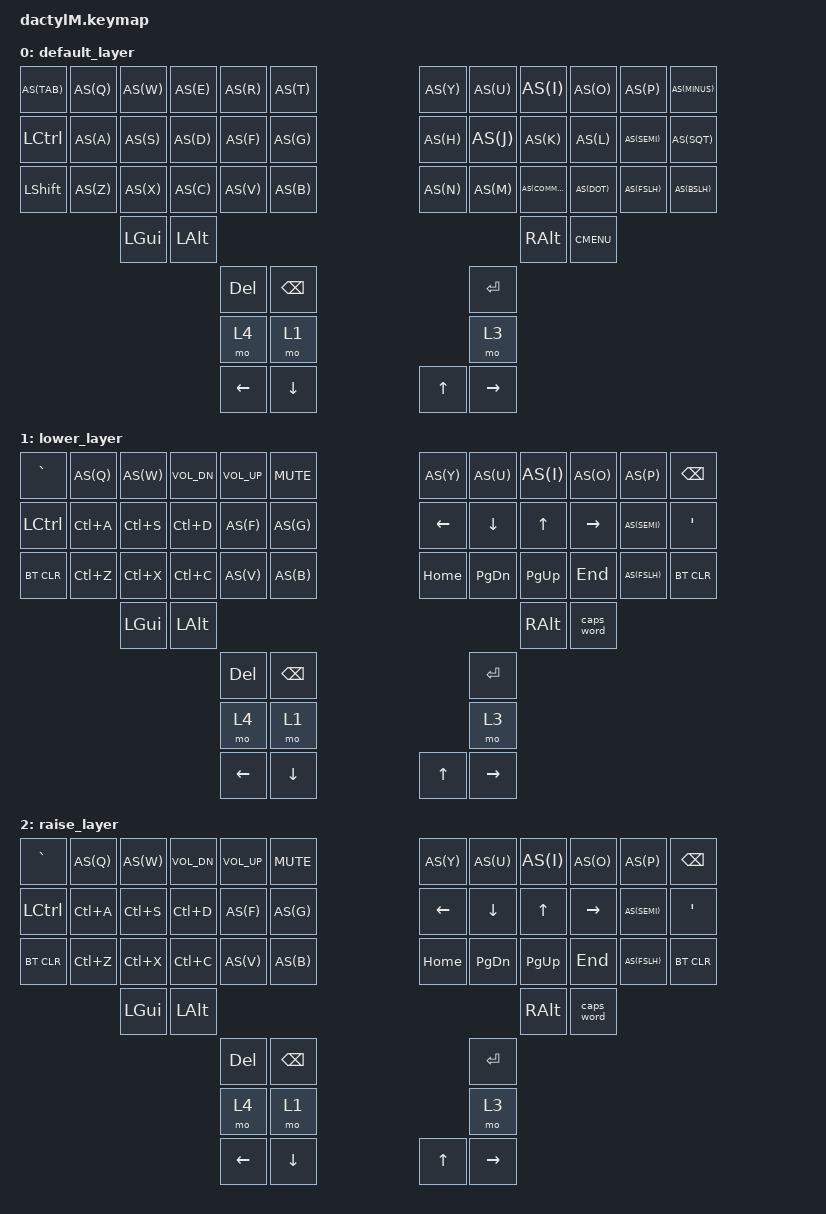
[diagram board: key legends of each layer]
/*
 * Copyright (c) 2020 The ZMK Contributors
 *
 * SPDX-License-Identifier: MIT
 */
/**/

#include <behaviors.dtsi>
#include <dt-bindings/zmk/keys.h>
#include <dt-bindings/zmk/bt.h>



#define DEFAULT 0
#define Movement 1
#define NumPad 2
#define Macro 3
#define Mouse 4

#define AS(keycode) &as LS(keycode) keycode

/ {
        behaviors {
            as: auto_shift {
                compatible = "zmk,behavior-hold-tap";
                label = "AUTO_SHIFT";
                #binding-cells = <2>;
                tapping_term_ms = <200>;
                quick_tap_ms = <10>;
                flavor = "tap-preferred";
                bindings = <&kp>, <&kp>;
            };
        };
        
        
    keymap {
        compatible = "zmk,keymap";

        default_layer {
// ------------------------------------------------------------------------------------------------------------
// |  TAB  |  Q  |  W  |  E   |  R   |  T    |                   |  Y   |  U     |  I    |  O   |   P   | BKSPC  |
// |  CTRL |  A  |  S  |  D   |  F   |  G    |                   |  H   |  J     |  K    |  L   |   ;   |   '    |
// | SHIFT |  Z  |  X  |  C   |  V   |  B    |                   |  N   |  M     |  ,    |  .   |   /   | SHIFT  |
//               | GUI | ALT  |                                                  | ALT   | GUI  |
//                            | DEL  | BKSPC |                   		|  ENTR  |
//                            | Lyr4 | Lyr1  |                   		| Lyr3  |
//                            | LEFT | DOWN  |                   | UP    | RIGHT |
            bindings = <
AS(TAB)   AS(Q)  AS(W)    AS(E)    AS(R)     AS(T)                       AS(Y)  AS(U)     AS(I)     AS(O)    AS(P)    AS(MINUS)
&kp LCTRL AS(A)  AS(S)    AS(D)    AS(F)     AS(G)                       AS(H)  AS(J)     AS(K)     AS(L)    AS(SEMI) AS(SQT)
&kp LSHFT AS(Z)  AS(X)    AS(C)    AS(V)     AS(B)                       AS(N)  AS(M)     AS(COMMA) AS(DOT)  AS(FSLH) AS(BSLH)
                 &kp LGUI &kp LALT                                                        &kp RALT  &kp K_CMENU
                                    &kp DELETE&kp BSPC                    		  &kp ENTER
                                    &mo 4     &mo 1                       		  &mo 3 
                                    &kp LEFT   &kp DOWN                   &kp UP  &kp RIGHT  
            >;
        };

        lower_layer {
// TODO: Some binds are waiting for shifted keycode support.
// ------------------------------------------------------------------------------------------------------------
// | `     |   1 |   2 |   3  |   4  |   5  |                   |   6  |   7   |   8   |   9  |    0  |  F12  |
// |       |  !  |  @  |  #   |  $   |  %   |                   |  ^   |  &    |  *    |  (   |   )   |   |   |
// |       |  =  |  -  |  +   |  {   |  }   |        |  |       |  [   |  ]    |  ;    |  :   |   \   |       |
//               |     |      |      |      |        |  |       |      |       |       |      |
           bindings = <
&kp GRAVE   AS(Q)      AS(W)     &kp K_VOL_DN &kp K_VOL_UP  &kp K_MUTE                   AS(Y)    AS(U)     AS(I)     AS(O)      AS(P)    &kp BSPC
&kp LCTRL   &kp LC(A)  &kp LC(S) &kp LC(D) AS(F)  AS(G)                   &kp LEFT &kp DOWN  &kp UP    &kp RIGHT AS(SEMI) &kp SQT
&bt BT_CLR  &kp LC(Z)  &kp LC(X) &kp LC(C) AS(V)  AS(B)                   &kp HOME &kp PG_DN &kp PG_UP &kp END    AS(FSLH) &bt BT_CLR
                       &kp LGUI  &kp LALT                                                    &kp RALT  &caps_word
                                   &kp DELETE  &kp BSPC                   		   &kp ENTER
                                   &mo 4       &mo 1                      		   &mo 3 
                                   &kp LEFT    &kp DOWN                   &kp UP  &kp RIGHT                
            >;
       
        };

        raise_layer {
// ------------------------------------------------------------------------------------------------------------
// |     | INS  | PSCR | GUI   |       |      |                | PGUP |      |   ^   |      |       |       |
// |     | ALT  | CTRL | SHIFT |       | CAPS |                | PGDN |   <- |   v   |  ->  |  DEL  | BKSPC |
// |     | UNDO | CUT  | COPY  | PASTE |      |      |  |      |      |      |       |      |       |       |
//              |      |       |       |      |      |  |      |      |      |       |      |
           bindings = <
&kp GRAVE   AS(Q)      AS(W)     &kp K_VOL_DN &kp K_VOL_UP  &kp K_MUTE                   AS(Y)    AS(U)     AS(I)     AS(O)      AS(P)    &kp BSPC
&kp LCTRL   &kp LC(A)  &kp LC(S) &kp LC(D) AS(F)  AS(G)                   &kp LEFT &kp DOWN  &kp UP    &kp RIGHT AS(SEMI) &kp SQT
&bt BT_CLR  &kp LC(Z)  &kp LC(X) &kp LC(C) AS(V)  AS(B)                   &kp HOME &kp PG_DN &kp PG_UP &kp END    AS(FSLH) &bt BT_CLR
                       &kp LGUI  &kp LALT                                                    &kp RALT  &caps_word
                                   &kp DELETE  &kp BSPC                   		   &kp ENTER
                                   &mo 4       &mo 1                      		   &mo 3 
                                   &kp LEFT    &kp DOWN                   &kp UP  &kp RIGHT                  
            >;
  
        };
    };
};
